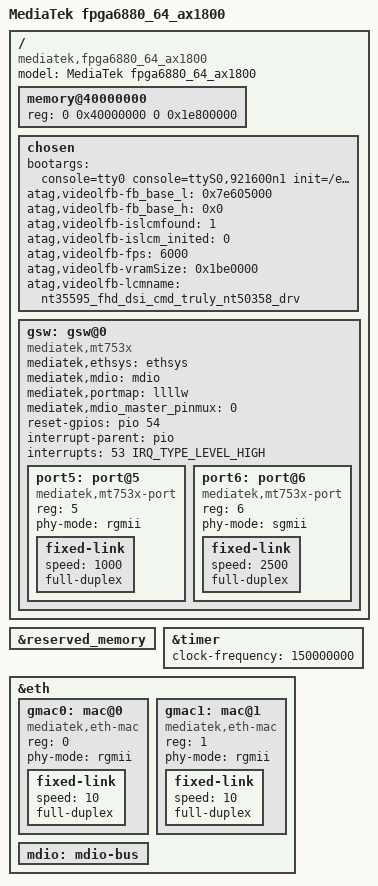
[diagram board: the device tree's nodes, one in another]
// SPDX-License-Identifier: GPL-2.0
/*
 * Copyright (c) 2019 MediaTek Inc.
 */

/dts-v1/;
#include <dt-bindings/interrupt-controller/irq.h>
#include <dt-bindings/interrupt-controller/arm-gic.h>
#include "mt6880.dtsi"

&reserved_memory {
};

/ {
	model = "MediaTek fpga6880_64_ax1800";
	compatible = "mediatek,fpga6880_64_ax1800", "mediatek,mt6880";

	memory@40000000 {
		device_type = "memory";
		reg = <0 0x40000000 0 0x1e800000>;
	};

	chosen {
		bootargs = "console=tty0 console=ttyS0,921600n1 \
		init=/etc/preinit root=/dev/mmcblk0p31 \
		loglevel=8 \
		androidboot.selinux=permissive androidboot.hardware=mt6880 \
		earlycon=mtk8250,mmio32,0x11002000 \
		mtk_printk_ctrl.disable_uart=0 \
		initcall_debug=1";

		atag,videolfb-fb_base_l = <0x7e605000>;
		atag,videolfb-fb_base_h = <0x0>;
		atag,videolfb-islcmfound = <1>;
		atag,videolfb-islcm_inited = <0>;
		atag,videolfb-fps= <6000>;
		atag,videolfb-vramSize= <0x1be0000>;
		atag,videolfb-lcmname=
			"nt35595_fhd_dsi_cmd_truly_nt50358_drv";
	};

	gsw: gsw@0 {
		compatible = "mediatek,mt753x";
		mediatek,ethsys = <&ethsys>;
		#address-cells = <1>;
		#size-cells = <0>;
	};
};

&timer {
	clock-frequency = <150000000>;
};

&eth {
	status = "okay";
	gmac0: mac@0 {
		compatible = "mediatek,eth-mac";
		reg = <0>;
		phy-mode = "rgmii";
		fixed-link {
			speed = <10>;
			full-duplex;
		};
	};
	gmac1: mac@1 {
		compatible = "mediatek,eth-mac";
		reg = <1>;
		phy-mode = "rgmii";
		fixed-link {
			speed = <10>;
			full-duplex;
		};
	};
	mdio: mdio-bus {
		#address-cells = <1>;
		#size-cells = <0>;
	};
};

&gsw {
	mediatek,mdio = <&mdio>;
	mediatek,portmap = "llllw";
	mediatek,mdio_master_pinmux = <0>;
	reset-gpios = <&pio 54 0>;
	interrupt-parent = <&pio>;
	interrupts = <53 IRQ_TYPE_LEVEL_HIGH>;
	status = "okay";

	port5: port@5 {
		compatible = "mediatek,mt753x-port";
		reg = <5>;
		phy-mode = "rgmii";
		fixed-link {
			speed = <1000>;
			full-duplex;
		};
	};

	port6: port@6 {
		compatible = "mediatek,mt753x-port";
		reg = <6>;
		phy-mode = "sgmii";
		fixed-link {
			speed = <2500>;
			full-duplex;
		};
	};
};
/*
&odm {
	vibrator0:vibrator@0 {
		compatible = "mediatek,vibrator";
		vib_timer = <25>;
		vib_limit = <9>;
		vib_vol= <9>;
	};
};*/

/* DISPSYS GPIO standardization */
#if 0
&pio {
	mtkfb_pins_lcd_bias_enp1: lcd_bias_enp1_gpio {
		pins_cmd_dat {
			pinmux = <PINMUX_GPIO28__FUNC_GPIO28>;
			slew-rate = <1>;
			output-high;
		};
	};

	mtkfb_pins_lcd_bias_enp0: lcd_bias_enp0_gpio {
		pins_cmd_dat {
			pinmux = <PINMUX_GPIO28__FUNC_GPIO28>;
			slew-rate = <1>;
			output-low;
		};
	};

	mtkfb_pins_lcd_bias_enn1: lcd_bias_enn1_gpio {
		pins_cmd_dat {
			pinmux = <PINMUX_GPIO29__FUNC_GPIO29>;
			slew-rate = <1>;
			output-high;
		};
	};

	mtkfb_pins_lcd_bias_enn0: lcd_bias_enn0_gpio {
		pins_cmd_dat {
			pinmux = <PINMUX_GPIO29__FUNC_GPIO29>;
			slew-rate = <1>;
			output-low;
		};
	};

	mtkfb_pins_lcm_rst_out1_gpio: lcm_rst_out1_gpio {
		pins_cmd_dat {
			pinmux = <PINMUX_GPIO42__FUNC_GPIO42>;
			slew-rate = <1>;
			output-high;
		};
	};

	mtkfb_pins_lcm_rst_out0_gpio: lcm_rst_out0_gpio {
		pins_cmd_dat {
			pinmux = <PINMUX_GPIO42__FUNC_GPIO42>;
			slew-rate = <1>;
			output-low;
		};
	};
	mtkfb_pins_lcm_dsi_te: lcm_dsi_te {
		pins_cmd_dat {
			pinmux = <PINMUX_GPIO41__FUNC_DSI_TE>;
		};
	};
};

&mtkfb {
	pinctrl-names = "lcd_bias_enp1_gpio", "lcd_bias_enp0_gpio",
		"lcd_bias_enn1_gpio", "lcd_bias_enn0_gpio",
		"lcm_rst_out1_gpio", "lcm_rst_out0_gpio",
		"mode_te_te";
	pinctrl-0 = <&mtkfb_pins_lcd_bias_enp1>;
	pinctrl-1 = <&mtkfb_pins_lcd_bias_enp0>;
	pinctrl-2 = <&mtkfb_pins_lcd_bias_enn1>;
	pinctrl-3 = <&mtkfb_pins_lcd_bias_enn0>;
	pinctrl-4 = <&mtkfb_pins_lcm_rst_out1_gpio>;
	pinctrl-5 = <&mtkfb_pins_lcm_rst_out0_gpio>;
	pinctrl-6 = <&mtkfb_pins_lcm_dsi_te>;
	status = "okay";
};
#endif


/* GPS GPIO standardization start */
#if 0
&pio {
	gps_pins_default: gps_default {
	};

	gps_l1_lna_pins_ol: gps_l1_lna@0 {
		pins_cmd_dat {
			pinmux = <PINMUX_GPIO125__FUNC_GPIO125>;
			output-low;
		};
	};
	gps_l1_lna_pins_dsp_ctrl: gps_l1_lna@1 {
		pins_cmd_dat {
			pinmux = <PINMUX_GPIO125__FUNC_GPS_L1_ELNA_EN>;
		};
	};
	gps_l1_lna_pins_oh: gps_l1_lna@2 {
		pins_cmd_dat {
			pinmux = <PINMUX_GPIO125__FUNC_GPIO125>;
			output-high;
		};
	};

	gps_l5_lna_pins_ol: gps_l5_lna@0 {
		pins_cmd_dat {
			pinmux = <PINMUX_GPIO126__FUNC_GPIO126>;
			output-low;
		};
	};
	gps_l5_lna_pins_dsp_ctrl: gps_l5_lna@1 {
		pins_cmd_dat {
			pinmux = <PINMUX_GPIO126__FUNC_GPS_L5_ELNA_EN>;
		};
	};
	gps_l5_lna_pins_oh: gps_l5_lna@2 {
		pins_cmd_dat {
			pinmux = <PINMUX_GPIO126__FUNC_GPIO126>;
			output-high;
		};
	};
};

&gps {
	pinctrl-names = "default",
		"gps_l1_lna_disable",
		"gps_l1_lna_dsp_ctrl",
		"gps_l1_lna_enable",
		"gps_l5_lna_disable",
		"gps_l5_lna_dsp_ctrl",
		"gps_l5_lna_enable";
	pinctrl-0 = <&gps_pins_default>;
	pinctrl-1 = <&gps_l1_lna_pins_ol>;
	pinctrl-2 = <&gps_l1_lna_pins_dsp_ctrl>;
	pinctrl-3 = <&gps_l1_lna_pins_oh>;
	pinctrl-4 = <&gps_l5_lna_pins_ol>;
	pinctrl-5 = <&gps_l5_lna_pins_dsp_ctrl>;
	pinctrl-6 = <&gps_l5_lna_pins_oh>;
	status = "okay";
};
#endif
/* GPS GPIO standardization end */

/*End of this file, DO NOT ADD ANYTHING HERE*/
